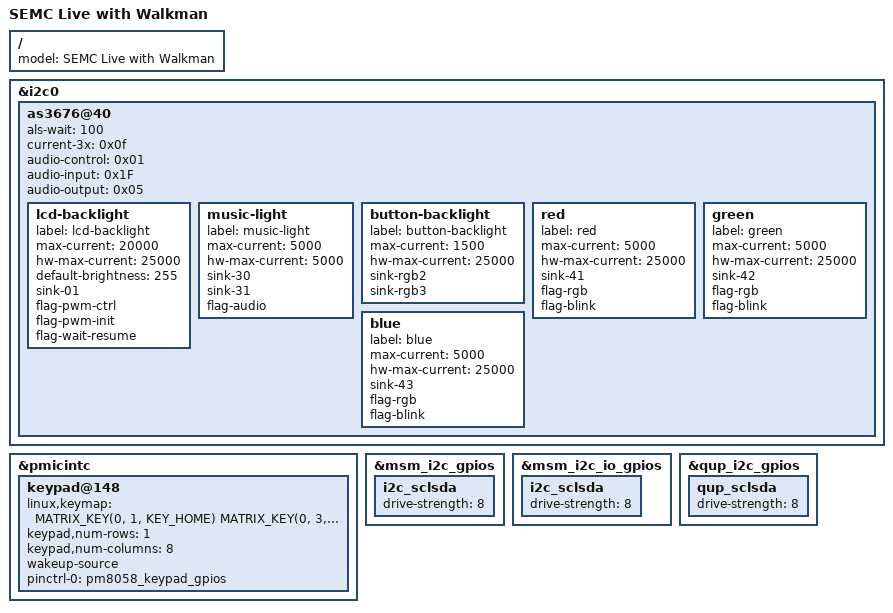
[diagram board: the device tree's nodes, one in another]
#include "qcom-msm7x30-semc-mogami.dtsi"

#include <dt-bindings/input/input.h>

/ {
	model = "SEMC Live with Walkman";
};

&i2c0 {
	as3676@40 {
		als-wait = <100>;

		current-3x = <0x0f>;
		audio-control = <0x01>;
		audio-input = <0x1F>;
		audio-output = <0x05>;

		lcd-backlight {
			label = "lcd-backlight";
			max-current = <20000>;
			hw-max-current = <25000>;
			default-brightness = <255>;
			sink-01;
			flag-pwm-ctrl;
			flag-pwm-init;
			flag-wait-resume;
		};

		music-light {
			label = "music-light";
			max-current = <5000>;
			hw-max-current = <5000>;
			sink-30;
			sink-31;
			flag-audio;
		};

		button-backlight {
			label = "button-backlight";
			max-current = <1500>;
			hw-max-current = <25000>;
			sink-rgb2;
			sink-rgb3;
		};

		red {
			label = "red";
			max-current = <5000>;
			hw-max-current = <25000>;
			sink-41;
			flag-rgb;
			flag-blink;
		};

		green {
			label = "green";
			max-current = <5000>;
			hw-max-current = <25000>;
			sink-42;
			flag-rgb;
			flag-blink;
		};

		blue {
			label = "blue";
			max-current = <5000>;
			hw-max-current = <25000>;
			sink-43;
			flag-rgb;
			flag-blink;
		};
	};
};

&pmicintc {
	keypad@148 {
		linux,keymap = <
			MATRIX_KEY(0, 1, KEY_HOME)
			MATRIX_KEY(0, 3, KEY_VOLUMEUP)
			MATRIX_KEY(0, 4, KEY_VOLUMEDOWN)
			MATRIX_KEY(0, 5, KEY_CAMERA_FOCUS)
			MATRIX_KEY(0, 6, KEY_CAMERA)
			MATRIX_KEY(0, 7, KEY_PLAYCD)
			>;
		keypad,num-rows = <1>;
		keypad,num-columns = <8>;
		wakeup-source;

		pinctrl-names = "default";
		pinctrl-0 = <&pm8058_keypad_gpios>;
	};
};

&msm_i2c_gpios {
	i2c_sclsda {
		drive-strength = <8>;
	};
};

&msm_i2c_io_gpios {
	i2c_sclsda {
		drive-strength = <8>;
	};
};

&qup_i2c_gpios {
	qup_sclsda {
		drive-strength = <8>;
	};
};
